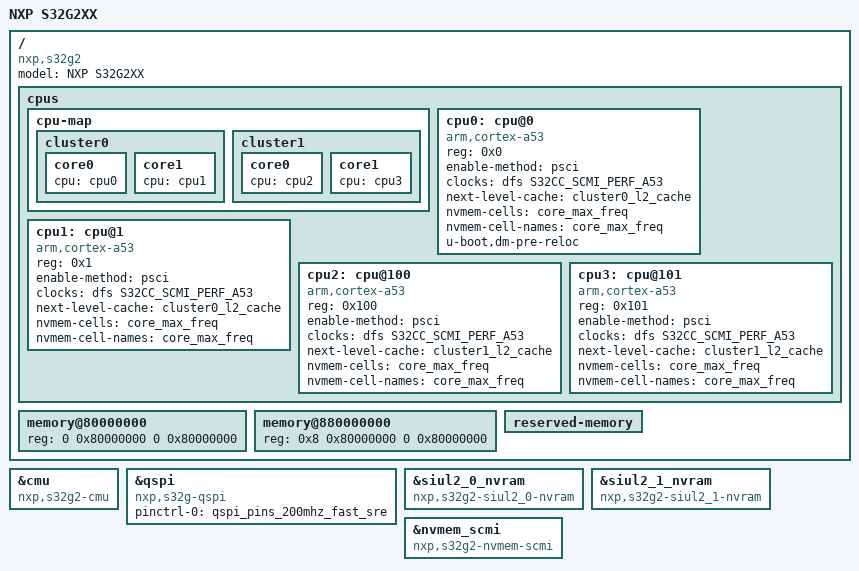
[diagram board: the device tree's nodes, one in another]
// SPDX-License-Identifier: (GPL-2.0+ OR BSD-3-Clause)
/*
 * Copyright 2021-2025 NXP
 */

#include "s32g.dtsi"
/ {
	model = "NXP S32G2XX";
	compatible = "nxp,s32g2";

	cpus {
		cpu-map {
			cluster0 {
				core0 {
					cpu = <&cpu0>;
				};

				core1 {
					cpu = <&cpu1>;
				};
			};

			cluster1 {
				core0 {
					cpu = <&cpu2>;
				};

				core1 {
					cpu = <&cpu3>;
				};
			};
		};

		cpu0: cpu@0 {
			device_type = "cpu";
			compatible = "arm,cortex-a53";
			reg = <0x0>;
			enable-method = "psci";
			clocks = <&dfs S32CC_SCMI_PERF_A53>;
			next-level-cache = <&cluster0_l2_cache>;

			nvmem-cells = <&core_max_freq>;
			nvmem-cell-names = "core_max_freq";
			u-boot,dm-pre-reloc;
		};

		cpu1: cpu@1 {
			device_type = "cpu";
			compatible = "arm,cortex-a53";
			reg = <0x1>;
			enable-method = "psci";
			clocks = <&dfs S32CC_SCMI_PERF_A53>;
			next-level-cache = <&cluster0_l2_cache>;

			nvmem-cells = <&core_max_freq>;
			nvmem-cell-names = "core_max_freq";
		};

		cpu2: cpu@100 {
			device_type = "cpu";
			compatible = "arm,cortex-a53";
			reg = <0x100>;
			enable-method = "psci";
			clocks = <&dfs S32CC_SCMI_PERF_A53>;
			next-level-cache = <&cluster1_l2_cache>;

			nvmem-cells = <&core_max_freq>;
			nvmem-cell-names = "core_max_freq";
		};

		cpu3: cpu@101 {
			device_type = "cpu";
			compatible = "arm,cortex-a53";
			reg = <0x101>;
			enable-method = "psci";
			clocks = <&dfs S32CC_SCMI_PERF_A53>;
			next-level-cache = <&cluster1_l2_cache>;

			nvmem-cells = <&core_max_freq>;
			nvmem-cell-names = "core_max_freq";
		};
	};

	memory@80000000 {
		device_type = "memory";
		reg = <0 0x80000000 0 0x80000000>;
	};

	memory@880000000 {
		device_type = "memory";
		reg = <0x8 0x80000000 0 0x80000000>;
	};

	reserved-memory {
		#address-cells = <2>;
		#size-cells = <2>;
		ranges;
	};
};

&cmu {
	compatible = "nxp,s32g2-cmu";
};

&qspi {
	compatible = "nxp,s32g-qspi", "nxp,s32cc-qspi";
	pinctrl-names = "default";
	pinctrl-0 = <&qspi_pins_200mhz_fast_sre>;
};

&siul2_0_nvram {
	compatible = "nxp,s32g2-siul2_0-nvram";
};

&siul2_1_nvram {
	compatible = "nxp,s32g2-siul2_1-nvram";
};

&nvmem_scmi {
	compatible = "nxp,s32g2-nvmem-scmi";
};
